AUTOSAR XML (schema 4.0)
package /Swcs
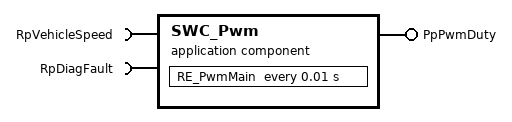
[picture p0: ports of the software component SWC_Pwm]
  application sw component type SWC_Pwm
    provide port PpPwmDuty
    require port RpVehicleSpeed
    require port RpDiagFault
    behavior IB_SWC_Pwm
      timing event TE_RE_PwmMain: start-on-event=RE_PwmMain, period=0.01
      runnable RE_PwmMain: symbol=Pwm_MainFunction
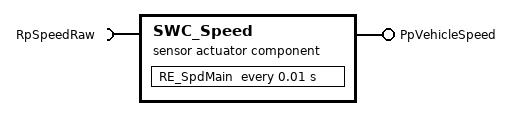
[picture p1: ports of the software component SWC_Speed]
  sensor actuator sw component type SWC_Speed
    provide port PpVehicleSpeed
    require port RpSpeedRaw
    behavior IB_SWC_Speed
      timing event TE_RE_SpdMain: start-on-event=RE_SpdMain, period=0.01
      runnable RE_SpdMain: symbol=Spd_MainFunction
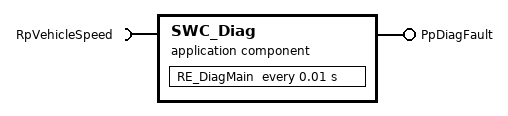
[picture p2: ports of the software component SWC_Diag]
  application sw component type SWC_Diag
    provide port PpDiagFault
    require port RpVehicleSpeed
    behavior IB_SWC_Diag
      timing event TE_RE_DiagMain: start-on-event=RE_DiagMain, period=0.01
      runnable RE_DiagMain: symbol=Diag_MainFunction
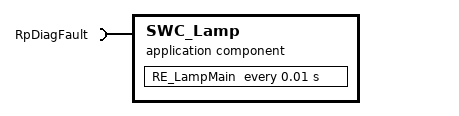
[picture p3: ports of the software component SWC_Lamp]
  application sw component type SWC_Lamp
    require port RpDiagFault
    behavior IB_SWC_Lamp
      timing event TE_RE_LampMain: start-on-event=RE_LampMain, period=0.01
      runnable RE_LampMain: symbol=Lamp_MainFunction
  composition sw component type Comp_Chassis
    component Pwm: type=SWC_Pwm
    component Speed: type=SWC_Speed
  composition sw component type Comp_Safety
    component Diag: type=SWC_Diag
  composition sw component type Comp_Body
    component Lamp: type=SWC_Lamp
  swc implementation Impl_Diag: behavior=IB_SWC_Diag
    code-descriptors:
      code Src: artifact-descriptors=autosar-engineering-object={short-label=diag.c, category=SWSRC}
